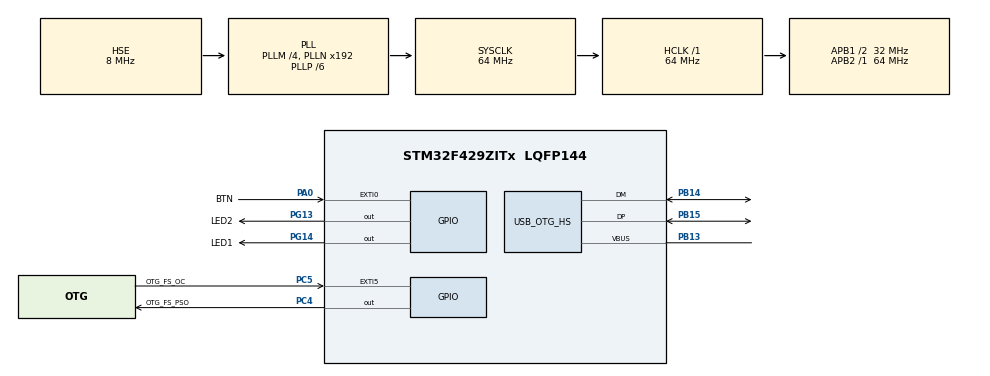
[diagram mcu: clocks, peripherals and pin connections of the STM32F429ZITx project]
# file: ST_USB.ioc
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Mcu.Family=STM32F4
Mcu.Name=STM32F429ZITx
Mcu.Package=LQFP144
NVIC.OTG_HS_IRQn=true\:0\:0\:false\:false\:true\:false\:true
NVIC.PriorityGroup=NVIC_PRIORITYGROUP_4
NVIC.TIM1_UP_TIM10_IRQn=true\:0\:0\:false\:false\:true\:false\:true
NVIC.TimeBase=TIM1_UP_TIM10_IRQn
NVIC.TimeBaseIP=TIM1
PA0/WKUP.GPIO_Label=BTN
PA0/WKUP.Signal=GPXTI0
PB13.Mode=Activate_VBUS_FS
PB13.Signal=USB_OTG_HS_VBUS
PB14.Mode=Device_Only_FS
PB14.Signal=USB_OTG_HS_DM
PB15.Mode=Device_Only_FS
PB15.Signal=USB_OTG_HS_DP
PC4.GPIO_Label=OTG_FS_PSO
PC4.Signal=GPIO_Output
PC5.GPIO_Label=OTG_FS_OC
PC5.Signal=GPXTI5
PG13.GPIO_Label=LED2
PG13.Signal=GPIO_Output
PG14.GPIO_Label=LED1
PG14.Signal=GPIO_Output
PH0/OSC_IN.Mode=HSE-External-Oscillator
PH0/OSC_IN.Signal=RCC_OSC_IN
PH1/OSC_OUT.Mode=HSE-External-Oscillator
PH1/OSC_OUT.Signal=RCC_OSC_OUT
ProjectManager.HeapSize=0x200
ProjectManager.StackSize=0x400
ProjectManager.TargetToolchain=MDK-ARM V5.27
RCC.48MHZClocksFreq_Value=48000000
RCC.AHBFreq_Value=64000000
RCC.APB1CLKDivider=RCC_HCLK_DIV2
RCC.APB1Freq_Value=32000000
RCC.APB1TimFreq_Value=64000000
RCC.APB2Freq_Value=64000000
RCC.APB2TimFreq_Value=64000000
RCC.CortexFreq_Value=64000000
RCC.HCLKFreq_Value=64000000
RCC.HSE_VALUE=8000000
RCC.HSI_VALUE=16000000
RCC.LSE_VALUE=32768
RCC.PLLM=4
RCC.PLLP=RCC_PLLP_DIV6
RCC.PLLQ=8
RCC.SYSCLKFreq_VALUE=64000000
RCC.SYSCLKSource=RCC_SYSCLKSOURCE_PLLCLK
RCC.VCOOutputFreq_Value=384000000
USB_DEVICE.CLASS_NAME_HS=CUSTOM_HID
USB_DEVICE.PID_CUSTOMHID_HS=0x5750
USB_DEVICE.USBD_CUSTOMHID_OUTREPORT_BUF_SIZE-CUSTOM_HID_HS=32
USB_DEVICE.USBD_CUSTOM_HID_REPORT_DESC_SIZE-CUSTOM_HID_HS=32
USB_DEVICE.VID-CUSTOM_HID_HS=0x483
USB_DEVICE.VirtualMode-CUSTOM_HID_HS=CustomHid
USB_DEVICE.VirtualModeHS=Custom_Hid_HS
USB_OTG_HS.VirtualMode-Device_Only_FS=Device_Only_FS
VP_SYS_VS_tim1.Mode=TIM1
VP_USB_DEVICE_VS_USB_DEVICE_CUSTOM_HID_HS.Mode=CUSTOM_HID_HS
board=custom

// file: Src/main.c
/* USER CODE BEGIN Header */
/**
  ******************************************************************************
  * @file           : main.c
  * @brief          : Main program body
  ******************************************************************************
  * @attention
  *
  * <h2><center>&copy; Copyright (c) 2021 STMicroelectronics.
  * All rights reserved.</center></h2>
  *
  * This software component is licensed by ST under Ultimate Liberty license
  * SLA0044, the "License"; You may not use this file except in compliance with
  * the License. You may obtain a copy of the License at:
  *                             www.st.com/SLA0044
  *
  ******************************************************************************
  */
/* USER CODE END Header */

#include "main.h"
#include "usb_device.h"

/* USER CODE BEGIN Includes */
#include "usbd_customhid.h"

/* USER CODE END Includes */

/* USER CODE BEGIN PTD */
extern USBD_HandleTypeDef hUsbDeviceHS;

/* USER CODE END PTD */

/* USER CODE BEGIN PV */
uint8_t tx_data[32];

/* USER CODE END PV */

void SystemClock_Config(void);
static void MX_GPIO_Init(void);

int main(void)
{

  /* MCU Configuration--------------------------------------------------------*/

  /* Reset of all peripherals, Initializes the Flash interface and the Systick. */
  HAL_Init();

  /* Configure the system clock */
  SystemClock_Config();

  /* Initialize all configured peripherals */
  MX_GPIO_Init();
  MX_USB_DEVICE_Init();

  /* Infinite loop */
  while (1)
  {

    /* USER CODE BEGIN 3 */
		sprintf((char*)tx_data,"hakan\r\n");
		//USBD_CUSTOM_HID_SendReport(&hUsbDeviceHS,tx_data,sizeof(tx_data));
		HAL_Delay(500);
		HAL_GPIO_TogglePin(GPIOG, LED1_Pin);
  }
  /* USER CODE END 3 */
}

void SystemClock_Config(void)
{
  RCC_OscInitTypeDef RCC_OscInitStruct = {0};
  RCC_ClkInitTypeDef RCC_ClkInitStruct = {0};

  /** Configure the main internal regulator output voltage
  */
  __HAL_RCC_PWR_CLK_ENABLE();
  __HAL_PWR_VOLTAGESCALING_CONFIG(PWR_REGULATOR_VOLTAGE_SCALE3);
  /** Initializes the CPU, AHB and APB busses clocks
  */
  RCC_OscInitStruct.OscillatorType = RCC_OSCILLATORTYPE_HSE;
  RCC_OscInitStruct.HSEState = RCC_HSE_ON;
  RCC_OscInitStruct.PLL.PLLState = RCC_PLL_ON;
  RCC_OscInitStruct.PLL.PLLSource = RCC_PLLSOURCE_HSE;
  RCC_OscInitStruct.PLL.PLLM = 4;
  RCC_OscInitStruct.PLL.PLLN = 192;
  RCC_OscInitStruct.PLL.PLLP = RCC_PLLP_DIV6;
  RCC_OscInitStruct.PLL.PLLQ = 8;
  if (HAL_RCC_OscConfig(&RCC_OscInitStruct) != HAL_OK)
  {
    Error_Handler();
  }
  /** Initializes the CPU, AHB and APB busses clocks
  */
  RCC_ClkInitStruct.ClockType = RCC_CLOCKTYPE_HCLK|RCC_CLOCKTYPE_SYSCLK
                              |RCC_CLOCKTYPE_PCLK1|RCC_CLOCKTYPE_PCLK2;
  RCC_ClkInitStruct.SYSCLKSource = RCC_SYSCLKSOURCE_PLLCLK;
  RCC_ClkInitStruct.AHBCLKDivider = RCC_SYSCLK_DIV1;
  RCC_ClkInitStruct.APB1CLKDivider = RCC_HCLK_DIV2;
  RCC_ClkInitStruct.APB2CLKDivider = RCC_HCLK_DIV1;

  if (HAL_RCC_ClockConfig(&RCC_ClkInitStruct, FLASH_LATENCY_2) != HAL_OK)
  {
    Error_Handler();
  }
}

static void MX_GPIO_Init(void)
{
  GPIO_InitTypeDef GPIO_InitStruct = {0};

  /* GPIO Ports Clock Enable */
  __HAL_RCC_GPIOH_CLK_ENABLE();
  __HAL_RCC_GPIOA_CLK_ENABLE();
  __HAL_RCC_GPIOC_CLK_ENABLE();
  __HAL_RCC_GPIOB_CLK_ENABLE();
  __HAL_RCC_GPIOG_CLK_ENABLE();

  /*Configure GPIO pin Output Level */
  HAL_GPIO_WritePin(OTG_FS_PSO_GPIO_Port, OTG_FS_PSO_Pin, GPIO_PIN_SET);

  /*Configure GPIO pin Output Level */
  HAL_GPIO_WritePin(GPIOG, LED2_Pin|LED1_Pin, GPIO_PIN_RESET);

  /*Configure GPIO pin : BTN_Pin */
  GPIO_InitStruct.Pin = BTN_Pin;
  GPIO_InitStruct.Mode = GPIO_MODE_IT_RISING;
  GPIO_InitStruct.Pull = GPIO_NOPULL;
  HAL_GPIO_Init(BTN_GPIO_Port, &GPIO_InitStruct);

  /*Configure GPIO pin : OTG_FS_PSO_Pin */
  GPIO_InitStruct.Pin = OTG_FS_PSO_Pin;
  GPIO_InitStruct.Mode = GPIO_MODE_OUTPUT_PP;
  GPIO_InitStruct.Pull = GPIO_NOPULL;
  GPIO_InitStruct.Speed = GPIO_SPEED_FREQ_LOW;
  HAL_GPIO_Init(OTG_FS_PSO_GPIO_Port, &GPIO_InitStruct);

  /*Configure GPIO pin : OTG_FS_OC_Pin */
  GPIO_InitStruct.Pin = OTG_FS_OC_Pin;
  GPIO_InitStruct.Mode = GPIO_MODE_IT_RISING;
  GPIO_InitStruct.Pull = GPIO_NOPULL;
  HAL_GPIO_Init(OTG_FS_OC_GPIO_Port, &GPIO_InitStruct);

  /*Configure GPIO pins : LED2_Pin LED1_Pin */
  GPIO_InitStruct.Pin = LED2_Pin|LED1_Pin;
  GPIO_InitStruct.Mode = GPIO_MODE_OUTPUT_PP;
  GPIO_InitStruct.Pull = GPIO_NOPULL;
  GPIO_InitStruct.Speed = GPIO_SPEED_FREQ_LOW;
  HAL_GPIO_Init(GPIOG, &GPIO_InitStruct);

}

void HAL_TIM_PeriodElapsedCallback(TIM_HandleTypeDef *htim)
{
  if (htim->Instance == TIM1) {
    HAL_IncTick();
  }
}

void Error_Handler(void)
{
}

/************************ (C) COPYRIGHT STMicroelectronics *****END OF FILE****/
